# MK50DZ10 register map
Vendor: Freescale Semiconductor, Inc.; Series: Kinetis_K; File version: 1.6
CPU: CM4 r0p1, little endian, no MPU, no FPU, VTOR, 4 interrupt priority bits
Registers are 32-bit, read-write, reset 0x0 unless marked. A register's access mark holds for its fields unless they carry their own. Offsets are from the block's base; [hi:lo] are bit positions; {n}, {i} and the like mark numbered series; 'fields as' and 'values as' point back to an identical list; <NAME> marks a mode.

## I2S0 — Synchronous Serial Interface
Base 0x4002F000; register names take the prefix I2S0_
0x00 TX0 — I2S Transmit Data Registers 0
  [31:0] TX0 — I2S transmit data
0x04 TX1 — I2S Transmit Data Registers 1
  [31:0] TX1 — I2S transmit data
0x08 RX0 — I2S Receive Data Registers 0
  [31:0] RX0 — I2S Receive Data
0x0C RX1 — I2S Receive Data Registers 1
  [31:0] RX1 — I2S Receive Data
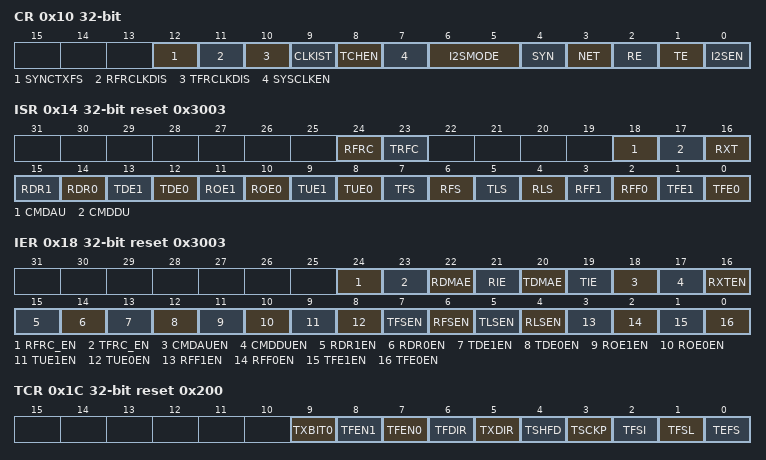
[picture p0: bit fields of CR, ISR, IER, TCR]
0x10 CR — I2S Control Register
  [12] SYNCTXFS
    0=CR[TE] not latched with FS occurrence and used directly for transmitter enable/disable; 1=CR[TE] latched with FS occurrence and latched-TE used for transmitter enable/disable
  [11] RFRCLKDIS — Receive Frame Clock Disable.
    0=Continue frame-sync/clock generation after current frame during which CR[RE] is cleared. This may be required when Frame-sync and Clocks are required from I2S, even when no data is to be received.; 1=Stop frame-sync/clock generation at next frame boundary. This will be effective also in case where receiver is already disabled in current or previous frames.
  [10] TFRCLKDIS — Transmit Frame Clock Disable.
    0=Continue frame-sync/clock generation after current frame during which CR[TE] is cleared. This may be required when frame-sync and clocks are required from I2S, even when no data is to be received.; 1=Stop frame-sync/clock generation at next frame boundary. This will be effective also in case where transmitter is already disabled in current or previous frames.
  [9] CLKIST — Clock Idle State.
    0=Clock idle state is `0'; 1=Clock idle state is `1'
  [8] TCHEN — Two-Channel Operation Enable.
    0=Two-channel mode disabled; 1=Two-channel mode enabled
  [7] SYSCLKEN — System Clock (Oversampling Clock) Enable.
    0=Network clock not output on SRCK port; 1=Network clock output on SRCK port
  [6:5] I2SMODE — I2S Mode Select
    0=Normal mode; 1=I2S master mode; 2=I2S slave mode; 3=Normal mode
  [4] SYN — Synchronous Mode.
    0=Asynchronous mode selected; 1=Synchronous mode selected
  [3] NET — Network Mode.
    0=Network mode not selected; 1=Network mode selected
  [2] RE — Receive Enable.
    0=Receive section disabled; 1=Receive section enabled
  [1] TE — Transmit Enable.
    0=Transmit section disabled; 1=Transmit section enabled
  [0] I2SEN — I2S Enable.
    0=I2S is disabled; 1=I2S is enabled
0x14 ISR reset 0x3003 — I2S Interrupt Status Register
  [24] RFRC — Receive Frame Complete.
    0=End of frame not reached; 1=End of frame reached after disabling CR[RE] or disabling CR[RFRCLKDIS], when receiver is already disabled
  [23] TRFC — Transmit Frame Complete.
    0=End of frame not reached; 1=End of frame reached after disabling CR[TE] or disabling CR[TFRCLKDIS], when transmitter is already disabled
  [18] CMDAU ro — Command Address Register Updated.
    0=No change in ACADD register; 1=ACADD register updated with different value
  [17] CMDDU ro — Command Data Register Updated.
    0=No change in ACDAT register; 1=ACDAT register updated with different value
  [16] RXT ro — Receive Tag Updated.
    0=No change in ATAG register; 1=ATAG register updated with different value
  [15] RDR1 ro — Receive Data Ready 1.
    0=No new data for core to read; 1=New data for core to read
  [14] RDR0 ro — Receive Data Ready 0.
    0=No new data for core to read; 1=New data for core to read
  [13] TDE1 ro — Transmit Data Register Empty 1.
    0=Data available for transmission; 1=Data needs to be written by the core for transmission
  [12] TDE0 ro — Transmit Data Register Empty 0.
    values as TDE1
  [11] ROE1 — Receiver Overrun Error 1.
    0=No overrun detected; 1=Receiver overrun error occurred
  [10] ROE0 — Receiver Overrun Error 0.
    0=No overrun detected; 1=Receiver overrun error occurred
  [9] TUE1 — Transmitter Underrun Error 1.
    0=No underrun detected; 1=Transmitter underrun error occurred
  [8] TUE0 — Transmitter Underrun Error 1.
    values as TUE1
  [7] TFS ro — Transmit Frame Sync.
    0=No occurrence of transmit frame sync; 1=Transmit frame sync occurred during transmission of last word written to TX registers
  [6] RFS ro — Receive Frame Sync.
    0=No occurrence of receive frame sync; 1=Receive frame sync occurred during reception of next word in RX registers
  [5] TLS ro — Transmit Last Time Slot.
    0=Current time slot is not last time slot of frame; 1=Current time slot is the last transmit time slot of frame
  [4] RLS ro — Receive Last Time Slot.
    0=Current time slot is not last time slot of frame; 1=Current time slot is the last receive time slot of frame
  [3] RFF1 ro — Receive FIFO Full 1.
    0=Space available in receive FIFO1; 1=Receive FIFO1 is full
  [2] RFF0 ro — Receive FIFO Full 0.
    0=Space available in receive FIFO0; 1=Receive FIFO0 is full
  [1] TFE1 ro — Transmit FIFO Empty 1.
    0=Transmit FIFO1 has data for transmission; 1=Transmit FIFO1 is empty
  [0] TFE0 ro — Transmit FIFO Empty 0.
    0=Transmit FIFO0 has data for transmission; 1=Transmit FIFO0 is empty
0x18 IER reset 0x3003 — I2S Interrupt Enable Register
  [24] RFRC_EN — Enable Bit.
    0=Corresponding status bit cannot issue interrupt; 1=Corresponding status bit can issue interrupt
  [23] TFRC_EN — Enable Bit.
    values as RFRC_EN
  [22] RDMAE — Receive DMA Enable.
    0=I2S receiver DMA requests disabled; 1=I2S receiver DMA requests enabled
  [21] RIE — Receive Interrupt Enable.
    0=I2S receiver interrupt requests disabled; 1=I2S receiver interrupt requests enabled
  [20] TDMAE — Transmit DMA Enable.
    0=I2S transmitter DMA requests disabled; 1=I2S transmitter DMA requests enabled
  [19] TIE — Transmit Interrupt Enable.
    0=I2S transmitter interrupt requests disabled; 1=I2S transmitter interrupt requests enabled
  [18] CMDAUEN — Enable Bit.
    values as RFRC_EN
  [17] CMDDUEN — Enable Bit.
    values as RFRC_EN
  [16] RXTEN — Enable Bit.
    values as RFRC_EN
  [15] RDR1EN — Enable Bit.
    values as RFRC_EN
  [14] RDR0EN — Enable Bit.
    values as RFRC_EN
  [13] TDE1EN — Enable Bit.
    values as RFRC_EN
  [12] TDE0EN — Enable Bit.
    values as RFRC_EN
  [11] ROE1EN — Enable Bit.
    values as RFRC_EN
  [10] ROE0EN — Enable Bit.
    values as RFRC_EN
  [9] TUE1EN — Enable Bit.
    values as RFRC_EN
  [8] TUE0EN — Enable Bit.
    values as RFRC_EN
  [7] TFSEN — Enable Bit.
    values as RFRC_EN
  [6] RFSEN — Enable Bit.
    values as RFRC_EN
  [5] TLSEN — Enable Bit.
    values as RFRC_EN
  [4] RLSEN — Enable Bit.
    values as RFRC_EN
  [3] RFF1EN — Enable Bit.
    values as RFRC_EN
  [2] RFF0EN — Enable Bit.
    values as RFRC_EN
  [1] TFE1EN — Enable Bit.
    values as RFRC_EN
  [0] TFE0EN — Enable Bit.
    values as RFRC_EN
0x1C TCR reset 0x200 — I2S Transmit Configuration Register
  [9] TXBIT0 — Transmit Bit 0.
    0=Shifting with respect to bit 31 (if word length = 16, 18, 20, 22 or 24) or bit 15 (if word length = 8, 10 or 12) of transmit shift register (MSB aligned); 1=Shifting with respect to bit 0 of transmit shift register (LSB aligned)
  [8] TFEN1 — Transmit FIFO Enable 1.
    0=Transmit FIFO 1 disabled; 1=Transmit FIFO 1 enabled
  [7] TFEN0 — Transmit FIFO Enable 0.
    0=Transmit FIFO 0 disabled; 1=Transmit FIFO 0 enabled
  [6] TFDIR — Transmit Frame Direction.
    0=Frame sync is external; 1=Frame sync generated internally
  [5] TXDIR — Transmit clock direction
    0=Transmit clock is external; 1=Transmit clock generated internally
  [4] TSHFD — Transmit Shift Direction.
    0=Data transmitted MSB first; 1=Data transmitted LSB first
  [3] TSCKP — Transmit Clock Polarity.
    0=Data clocked out on rising edge of bit clock; 1=Data clocked out on falling edge of bit clock
  [2] TFSI — Transmit Frame Sync Invert.
    0=Transmit frame sync is active high; 1=Transmit frame sync is active low
  [1] TFSL — Transmit Frame Sync Length.
    0=Transmit frame sync is one-word long; 1=Transmit frame sync is one-clock-bit long
  [0] TEFS — Transmit Early Frame Sync.
    0=Transmit frame sync initiated as the first bit of data is transmitted; 1=Transmit frame sync is initiated one bit before the data is transmitted
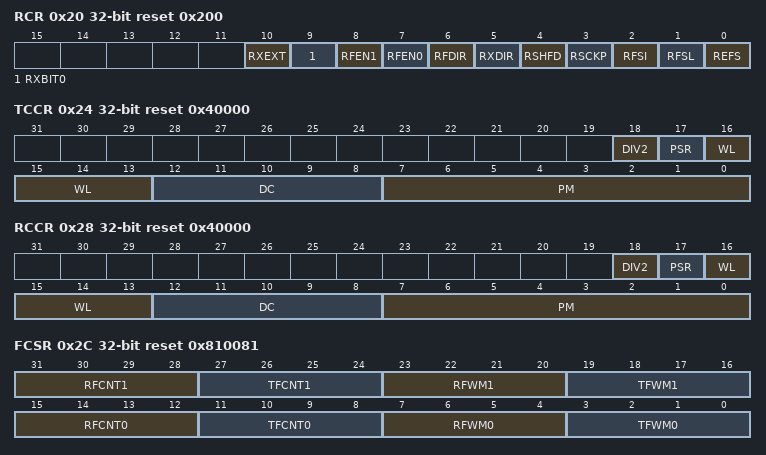
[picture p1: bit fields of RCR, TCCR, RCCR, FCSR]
0x20 RCR reset 0x200 — I2S Receive Configuration Register
  [10] RXEXT — Receive Data Extension.
    0=Sign extension turned off; 1=Sign extension turned on
  [9] RXBIT0 — Receive Bit 0.
    0=Shifting with respect to bit 31 (if word length = 16, 18, 20, 22 or 24) or bit 15 (if word length = 8, 10 or 12) of receive shift register (MSB aligned); 1=Shifting with respect to bit 0 of receive shift register (LSB aligned)
  [8] RFEN1 — Receive FIFO Enable 1.
    0=Receive FIFO 1 disabled; 1=Receive FIFO 1 enabled
  [7] RFEN0 — Receive FIFO Enable 0.
    0=Receive FIFO 0 disabled; 1=Receive FIFO 0 enabled
  [6] RFDIR — Receive Frame Direction.
    0=Frame Sync is external; 1=Frame Sync generated internally
  [5] RXDIR — Receive Clock Direction.
    0=Receive Clock is external; 1=Receive Clock generated internally
  [4] RSHFD — Receive Shift Direction.
    0=Data received MSB first; 1=Data received LSB first
  [3] RSCKP — Receive Clock Polarity.
    0=Data latched on falling edge of bit clock; 1=Data latched on rising edge of bit clock
  [2] RFSI — Receive Frame Sync Invert.
    0=Receive frame sync is active high; 1=Receive frame sync is active low
  [1] RFSL — Receive Frame Sync Length.
    0=Receive frame sync is one-word long; 1=Receive frame sync is one-clock-bit long
  [0] REFS — Receive Early Frame Sync.
    0=Receive frame sync initiated as the first bit of data is received; 1=Receive frame sync is initiated one bit before the data is received
0x24 TCCR reset 0x40000 — I2S Transmit Clock Control Registers
  [18] DIV2 — Divide By 2.
    0=Divider bypassed; 1=Divider used to divide clock by 2
  [17] PSR — Prescaler Range.
    0=Prescaler bypassed; 1=Prescaler used to divide clock by 8
  [16:13] WL — Word Length Control.
    0=Reserved. Do not program this value.; 1=Reserved. Do not program this value.; 2=Reserved. Do not program this value.; 3=8; 4=10; 5=12; 6=Reserved. Do not program this value.; 7=16; 8=18; 9=20; 10=22; 11=24; {v}=Reserved. Do not program this value. (v=12..15)
  [12:8] DC — Frame Rate Divider Control.
  [7:0] PM — Prescaler Modulus Select.
0x28 RCCR reset 0x40000 — I2S Receive Clock Control Registers
  [18] DIV2 — Divide By 2.
    0=Divider bypassed; 1=Divider used to divide clock by 2
  [17] PSR — Prescaler Range.
    0=Prescaler bypassed; 1=Prescaler used to divide clock by 8
  [16:13] WL — Word Length Control.
    0=Number of Bits/Word: 2; Supported in Implementation: No; 1=Number of Bits/Word: 4; Supported in Implementation: No; 2=Number of Bits/Word: 6; Supported in Implementation: No; 3=Number of Bits/Word: 8; Supported in Implementation: Yes; 4=Number of Bits/Word: 10; Supported in Implementation: Yes; 5=Number of Bits/Word: 12; Supported in Implementation: Yes; 6=Number of Bits/Word: 14; Supported in Implementation: No; 7=Number of Bits/Word: 16; Supported in Implementation: Yes; 8=Number of Bits/Word: 18; Supported in Implementation: Yes; 9=Number of Bits/Word: 20; Supported in Implementation: Yes; 10=Number of Bits/Word: 22; Supported in Implementation: Yes; 11=Number of Bits/Word: 24; Supported in Implementation: Yes; 12=Number of Bits/Word: 26; Supported in Implementation: No; 13=Number of Bits/Word: 28; Supported in Implementation: No; 14=Number of Bits/Word: 30; Supported in Implementation: No; 15=Number of Bits/Word: 32; Supported in Implementation: No
  [12:8] DC — Frame Rate Divider Control.
  [7:0] PM — Prescaler Modulus Select.
0x2C FCSR reset 0x810081 — I2S FIFO Control/Status Register
  [31:28] RFCNT1 — Receive FIFO Counter1.
    {v}={v} data word in receive FIFO (v=0..15)
  [27:24] TFCNT1 — Transmit FIFO Counter1.
    {v}={v} data word in transmit FIFO (v=0..15)
  [23:20] RFWM1 — Receive FIFO Full WaterMark 1.
    1=RFF set when at least one data word have been written to the Receive FIFO Set when RxFIFO = 1,2.....15 data words; {v}=RFF set when more than or equal to {v} data word have been written to the Receive FIFO. Set when RxFIFO = {v},{v+1}.....15 data words (v=2..5); 6=RFF set when more than or equal to 6 data word have been written to the Receive. Set when RxFIFO = 6,7......15 data words; 7=RFF set when more than or equal to 7 data word have been written to the Receive FIFO. Set when RxFIFO = 7,8......15 data words; 8=RFF set when more than or equal to 8 data word have been written to the Receive FIFO. Set when RxFIFO = 8,9......15 data words; {v}=RFF set when more than or equal to {v} data word have been written to the Receive FIFO. Set when RxFIFO = {v},{v+1}.....15 data words (v=9..12); 13=RFF set when more than or equal to 13 data word have been written to the Receive FIFO. Set when RxFIFO = 13,14,15data words; 14=RFF set when more than or equal to 14 data word have been written to the Receive FIFO. Set when RxFIFO = 14,15 data words; 15=RFF set when 15 data word have been written to the Receive FIFO (default). Set when RxFIFO = 15 data words
  [19:16] TFWM1 — Transmit FIFO Empty WaterMark 1.
    1=TFE set when there are more than or equal to 1 empty slots in Transmit FIFO. (default) Transmit FIFO empty is set when TxFIFO <= 14 data.; 2=TFE set when there are more than or equal to 2 empty slots in Transmit FIFO. (default) Transmit FIFO empty is set when TxFIFO <= 13 data.; 3=TFE set when there are more than or equal to 3 empty slots in Transmit FIFO. (default) Transmit FIFO empty is set when TxFIFO <= 12 data.; 4=TFE set when there are more than or equal to 4 empty slots in Transmit FIFO. (default) Transmit FIFO empty is set when TxFIFO <= 11 data.; 5=TFE set when there are more than or equal to 5 empty slots in Transmit FIFO. (default) Transmit FIFO empty is set when TxFIFO <= 10 data.; 6=TFE set when there are more than or equal to 6 empty slots in Transmit FIFO. (default) Transmit FIFO empty is set when TxFIFO <= 9 data.; 7=TFE set when there are more than or equal to 7 empty slots in Transmit FIFO. (default) Transmit FIFO empty is set when TxFIFO <= 8 data.; 8=TFE set when there are more than or equal to 8 empty slots in Transmit FIFO. (default) Transmit FIFO empty is set when TxFIFO <= 7 data.; 9=TFE set when there are more than or equal to 9 empty slots in Transmit FIFO. (default) Transmit FIFO empty is set when TxFIFO <= 6 data.; 10=TFE set when there are more than or equal to 10 empty slots in Transmit FIFO. (default) Transmit FIFO empty is set when TxFIFO <= 5 data.; 11=TFE set when there are more than or equal to 11 empty slots in Transmit FIFO. (default) Transmit FIFO empty is set when TxFIFO <= 4 data.; 12=TFE set when there are more than or equal to 12 empty slots in Transmit FIFO. (default) Transmit FIFO empty is set when TxFIFO <= 3 data.; 13=TFE set when there are more than or equal to 13 empty slots in Transmit FIFO. (default) Transmit FIFO empty is set when TxFIFO <= 2 data.; 14=TFE set when there are more than or equal to 14 empty slots in Transmit FIFO. (default) Transmit FIFO empty is set when TxFIFO <= 1 data.; 15=TFE set when there are more than or equal to 15 empty slots in Transmit FIFO. (default) Transmit FIFO empty is set when TxFIFO <= 0 data.
  [15:12] RFCNT0 — Receive FIFO Counter 0.
    {v}={v} data word in receive FIFO (v=0..15)
  [11:8] TFCNT0 — Transmit FIFO Counter 0.
    {v}={v} data word in transmit FIFO (v=0..15)
  [7:4] RFWM0 — Receive FIFO Full WaterMark 0.
    values as RFWM1
  [3:0] TFWM0 — Transmit FIFO Empty WaterMark 0.
    values as TFWM1
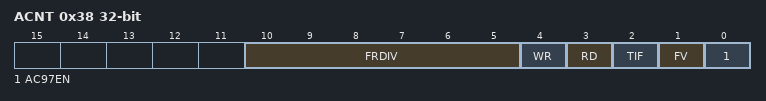
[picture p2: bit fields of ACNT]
0x38 ACNT — I2S AC97 Control Register
  [10:5] FRDIV — Frame Rate Divider.
  [4] WR — Write Command.
    0=Next frame will not have a Write Command; 1=Next frame will have a Write Command
  [3] RD — Read Command.
    0=Next frame will not have a Read Command; 1=Next frame will have a Read Command
  [2] TIF — Tag in FIFO.
    0=Tag info stored in ATAG register; 1=Tag info stored in ATAG register and Rx FIFO 0
  [1] FV — Fixed/Variable Operation.
    0=AC97 Fixed Mode; 1=AC97 Variable Mode
  [0] AC97EN — AC97 Mode Enable.
    0=AC97 mode disabled; 1=I2S in AC97 mode
0x3C ACADD — I2S AC97 Command Address Register
  [18:0] ACADD — AC97 Command Address.
0x40 ACDAT — I2S AC97 Command Data Register
  [19:0] ACDAT — AC97 Command Data.
0x44 ATAG — I2S AC97 Tag Register
  [15:0] ATAG — AC97 Tag Value.
0x48 TMSK — I2S Transmit Time Slot Mask Register
  [31:0] TMSK — Transmit Mask.
    0=Valid Time Slot; 1=Time Slot masked (no data transmitted in this time slot)
0x4C RMSK — I2S Receive Time Slot Mask Register
  [31:0] RMSK — Receive Mask.
    0=Valid Time Slot; 1=Time Slot masked (no data received in this time slot)
0x50 ACCST ro — I2S AC97 Channel Status Register
  [9:0] ACCST — AC97 Channel Status.
    0=Data channel disabled; 1=Data channel enabled
0x54 ACCEN — I2S AC97 Channel Enable Register
  [9:0] ACCEN wo — AC97 Channel Enable.
    0=Write has no effect; 1=Write enables the corresponding data channel
0x58 ACCDIS — I2S AC97 Channel Disable Register
  [9:0] ACCDIS wo — AC97 Channel Disable.
    0=Write has no effect; 1=Write disables the corresponding data channel
